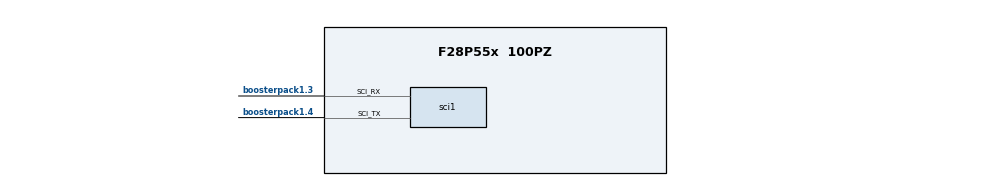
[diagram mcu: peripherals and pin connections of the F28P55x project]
/**
 *
 * @cliArgs --board "/boards/LAUNCHXL_F28P55X" --device "F28P55x" --part "F28P55x_100PZ" --package "100PZ" --context "system" --product "C2000WARE@26.01.00.00"
 * @versions {"tool":"1.28.1+4785"}
 */

/**
 * Import the modules used in this configuration.
 */
const npu  = scripting.addModule("/driverlib/npu.js", {}, false);
const npu1 = npu.addInstance();
const sci  = scripting.addModule("/driverlib/sci.js", {}, false);
const sci1 = sci.addInstance();

/**
 * Write custom configuration values to the imported modules.
 */
npu1.$name = "myNPU0";

sci1.$name                 = "mySCI0";
sci1.sci.sci_rxPin.$assign = "boosterpack1.3";
sci1.sci.sci_txPin.$assign = "boosterpack1.4";
sci1.rxQual.$name          = "myGPIOQUAL0";
sci1.txQual.$name          = "myGPIOQUAL1";
scripting.suppress("Connected to hardware,@@@.+?@@@ is connected to SCIA XDS on the LaunchPad F28P55X\\. Consider selecting it in \'use hardware\' above\\. @@@.+?@@@", sci1.sci, "sci_rxPin");
scripting.suppress("Connected to hardware,@@@.+?@@@ is connected to SCIA XDS on the LaunchPad F28P55X\\. Consider selecting it in \'use hardware\' above\\. @@@.+?@@@", sci1.sci, "sci_txPin");

/**
 * Pinmux solution for unlocked pins/peripherals. This ensures that minor changes to the automatic solver in a future
 * version of the tool will not impact the pinmux you originally saw.  These lines can be completely deleted in order to
 * re-solve from scratch.
 */
sci1.sci.$suggestSolution = "SCIA";
